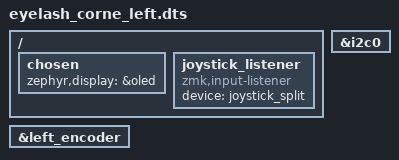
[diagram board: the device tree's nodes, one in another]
/*
*
* Copyright (c) 2024 The ZMK Contributors
* SPDX-License-Identifier: MIT
*
*/

#include "eyelash_corne.dtsi"

&left_encoder {
    status = "okay";
};

&i2c0 {
    status = "okay";
};

/ {
    chosen {
        zephyr,display = &oled;
    };

    joystick_listener: joystick_listener {
        compatible = "zmk,input-listener";
        device = <&joystick_split>;
    };
};
